# phy_pcs_lane_registers: IP-XACT component
VLNV cadence:cdns_lib:phy_pcs_lane_registers:1685-2009

## Address spaces and blocks
sd3101_t4_registers.sd3101_phy_registers: base 0x34000, range 0x3ff, width 32

## Registers
Registers are 32-bit, read-write, reset 0x0 unless marked. A register's access mark holds for its fields unless they carry their own. Offsets are from the block's base; lines under a group give offsets from that group; [hi:lo] are bit positions; {n}, {i} and the like mark numbered series; 'fields as' and 'values as' point back to an identical list; <NAME> marks a mode.

## sd3101_t4_registers.sd3101_phy_registers
Base 0x00034000
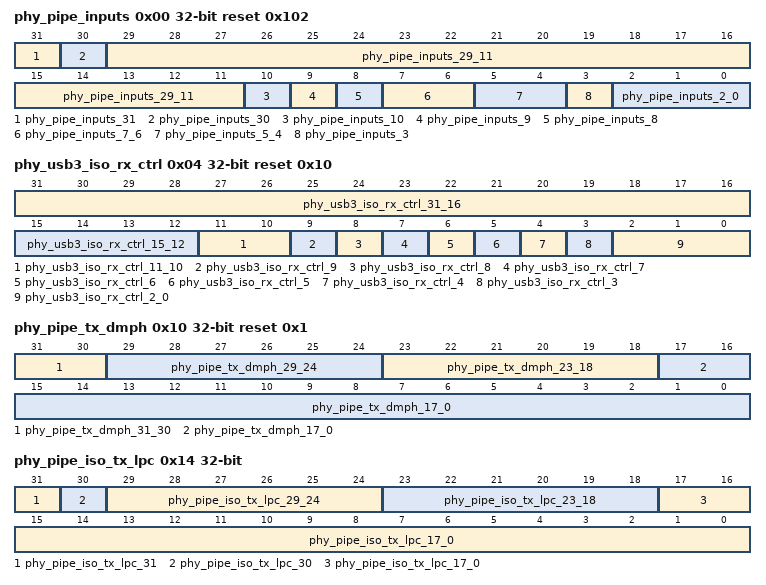
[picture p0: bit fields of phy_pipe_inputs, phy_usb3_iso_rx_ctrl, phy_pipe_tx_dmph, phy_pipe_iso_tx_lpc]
0x00 phy_pipe_inputs reset 0x102 — PIPE7 inputs register
  [31] phy_pipe_inputs_31 ro — RSVD2
  [30] phy_pipe_inputs_30 ro — CTLR_INT
  [29:11] phy_pipe_inputs_29_11 ro — RSVD
  [10] phy_pipe_inputs_10 ro — RX_TERM
  [9] phy_pipe_inputs_9 ro — TX_DET_RX
  [8] phy_pipe_inputs_8 ro — TX_ELEC_IDL
  [7:6] phy_pipe_inputs_7_6 ro — RSVD
  [5:4] phy_pipe_inputs_5_4 ro — RATE
  [3] phy_pipe_inputs_3 ro — RSVD
  [2:0] phy_pipe_inputs_2_0 ro — PWRDWN
0x04 phy_usb3_iso_rx_ctrl reset 0x10 — PHY USB3 RX control signal isolation register
  [31:16] phy_usb3_iso_rx_ctrl_31_16 ro — RSVD
  [15:12] phy_usb3_iso_rx_ctrl_15_12 ro — PIPE4_DATA_K
  [11:10] phy_usb3_iso_rx_ctrl_11_10 ro — RSVD
  [9] phy_usb3_iso_rx_ctrl_9 — PIPE4_RX_EQ
  [8] phy_usb3_iso_rx_ctrl_8 — PIPE4_RX_TERMINATION
  [7] phy_usb3_iso_rx_ctrl_7 — PIPE4_RX_POL
  [6] phy_usb3_iso_rx_ctrl_6 ro — RSVD
  [5] phy_usb3_iso_rx_ctrl_5 ro — PIPE4_RX_VALID
  [4] phy_usb3_iso_rx_ctrl_4 ro — PIPE4_RX_ELEC_IDLE
  [3] phy_usb3_iso_rx_ctrl_3 ro — RSVD
  [2:0] phy_usb3_iso_rx_ctrl_2_0 ro — PIPE4_RX_STATUS
0x10 phy_pipe_tx_dmph reset 0x1 — PIPE MB Tx deemphasis register
  [31:30] phy_pipe_tx_dmph_31_30 ro — RSVD
  [29:24] phy_pipe_tx_dmph_29_24 ro — TX_PRE_IDX
  [23:18] phy_pipe_tx_dmph_23_18 ro — RSVD
  [17:0] phy_pipe_tx_dmph_17_0 ro — TX_DEEMPH
0x14 phy_pipe_iso_tx_lpc — PIPE MB TX local preset coefficients isolation register
  [31] phy_pipe_iso_tx_lpc_31 ro — VALID
  [30] phy_pipe_iso_tx_lpc_30 — GET_PRESET
  [29:24] phy_pipe_iso_tx_lpc_29_24 — INDEX
  [23:18] phy_pipe_iso_tx_lpc_23_18 ro — RSVD0
  [17:0] phy_pipe_iso_tx_lpc_17_0 ro — COEFF
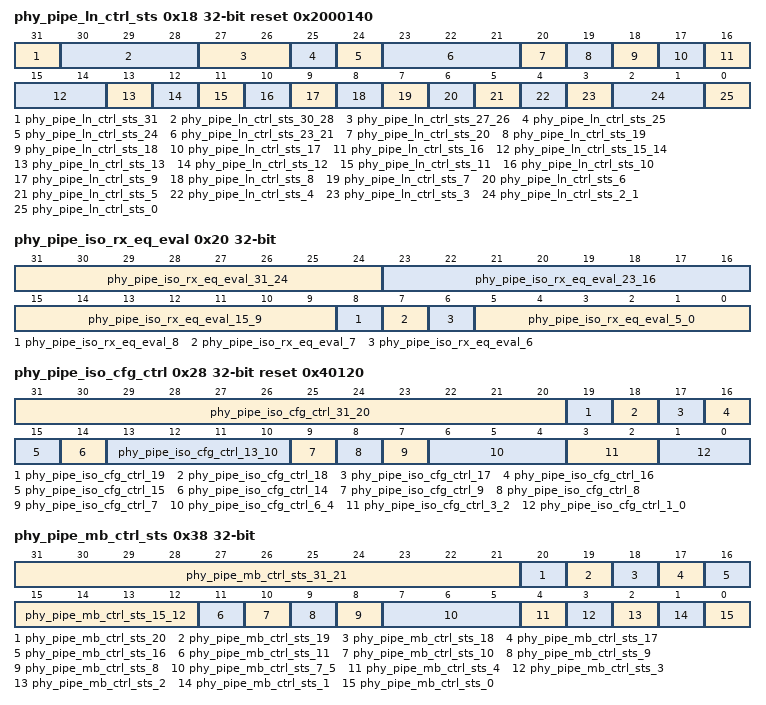
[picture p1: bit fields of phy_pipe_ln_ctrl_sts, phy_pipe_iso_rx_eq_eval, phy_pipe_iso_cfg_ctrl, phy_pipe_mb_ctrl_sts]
0x18 phy_pipe_ln_ctrl_sts reset 0x2000140 — PIPE lane control and status register
  [31] phy_pipe_ln_ctrl_sts_31 ro — TX_SWNG
  [30:28] phy_pipe_ln_ctrl_sts_30_28 ro — TX_MGN
  [27:26] phy_pipe_ln_ctrl_sts_27_26 ro — RSVD2
  [25] phy_pipe_ln_ctrl_sts_25 write-1-sets — SUSPEND_ACK
  [24] phy_pipe_ln_ctrl_sts_24 write-1-sets — DATA_PATH_OVD
  [23:21] phy_pipe_ln_ctrl_sts_23_21 ro — NELD_POS
  [20] phy_pipe_ln_ctrl_sts_20 ro — INVALID
  [19] phy_pipe_ln_ctrl_sts_19 write-1-sets — RX_IDL_OVD
  [18] phy_pipe_ln_ctrl_sts_18 write-1-sets — RX_IDL_VAL
  [17] phy_pipe_ln_ctrl_sts_17 write-1-sets — RX_VLD_OVD
  [16] phy_pipe_ln_ctrl_sts_16 write-1-sets — RX_VLD_VAL
  [15:14] phy_pipe_ln_ctrl_sts_15_14 ro — RSVD0
  [13] phy_pipe_ln_ctrl_sts_13 write-1-sets — LN_MGN_SEL
  [12] phy_pipe_ln_ctrl_sts_12 ro — NELD_ENABLE
  [11] phy_pipe_ln_ctrl_sts_11 ro — GET_TX_COEFF
  [10] phy_pipe_ln_ctrl_sts_10 ro — RXEQ_TRN
  [9] phy_pipe_ln_ctrl_sts_9 ro — IORECAL
  [8] phy_pipe_ln_ctrl_sts_8 ro — PHY_STATUS
  [7] phy_pipe_ln_ctrl_sts_7 ro — RSVD
  [6] phy_pipe_ln_ctrl_sts_6 write-1-sets — FS_LF_VLD
  [5] phy_pipe_ln_ctrl_sts_5 ro — TX_COEFF_VLD
  [4] phy_pipe_ln_ctrl_sts_4 ro — RSVD
  [3] phy_pipe_ln_ctrl_sts_3 write-1-sets — RXEQEVAL_SEL
  [2:1] phy_pipe_ln_ctrl_sts_2_1 ro — RSVD
  [0] phy_pipe_ln_ctrl_sts_0 ro — RXEQEVAL_CMP
0x1C phy_pipe_ln_ctrl_sts_clr reset 0x8C — PIPE lane control and status clear register
  [31:0] phy_pipe_ln_ctrl_sts_clr_31_0 write-1-clears — CLR
0x20 phy_pipe_iso_rx_eq_eval — PIPE RX equalization evaluation isolation register
  [31:24] phy_pipe_iso_rx_eq_eval_31_24 ro — RSVD2
  [23:16] phy_pipe_iso_rx_eq_eval_23_16 ro — FOM
  [15:9] phy_pipe_iso_rx_eq_eval_15_9 ro — RSVD1
  [8] phy_pipe_iso_rx_eq_eval_8 — RXEQEVAL
  [7] phy_pipe_iso_rx_eq_eval_7 ro — RSVD0
  [6] phy_pipe_iso_rx_eq_eval_6 ro — RXEQEVAL_CMP
  [5:0] phy_pipe_iso_rx_eq_eval_5_0 ro — DIR_CHG
0x24 phy_usb3_iso_tx_data — PHY USB3 TX Data isolation register
  [31:0] phy_usb3_iso_tx_data_31_0 — TX_DATA
0x28 phy_pipe_iso_cfg_ctrl reset 0x40120 — PIPE7 configuration and control signal isolation register
  [31:20] phy_pipe_iso_cfg_ctrl_31_20 ro — RSVD
  [19] phy_pipe_iso_cfg_ctrl_19 — STAND_BY
  [18] phy_pipe_iso_cfg_ctrl_18 ro — RX_ELEC_IDL
  [17] phy_pipe_iso_cfg_ctrl_17 ro — RX_VALID
  [16] phy_pipe_iso_cfg_ctrl_16 — RX_TERM
  [15] phy_pipe_iso_cfg_ctrl_15 — TX_CMN_MD_DIS
  [14] phy_pipe_iso_cfg_ctrl_14 — RX_IDL_DET_DIS
  [13:10] phy_pipe_iso_cfg_ctrl_13_10 ro — RSVD2
  [9] phy_pipe_iso_cfg_ctrl_9 — TX_DET_RX
  [8] phy_pipe_iso_cfg_ctrl_8 — TX_ELEC_IDLE
  [7] phy_pipe_iso_cfg_ctrl_7 ro — RSVD1
  [6:4] phy_pipe_iso_cfg_ctrl_6_4 — PWRDN
  [3:2] phy_pipe_iso_cfg_ctrl_3_2 ro — RSVD0
  [1:0] phy_pipe_iso_cfg_ctrl_1_0 — RATE
0x38 phy_pipe_mb_ctrl_sts — PHY PIPE messagebus control and status register
  [31:21] phy_pipe_mb_ctrl_sts_31_21 ro — RSVD
  [20] phy_pipe_mb_ctrl_sts_20 ro — WR_ACK_RCVD
  [19] phy_pipe_mb_ctrl_sts_19 ro — COM_WR_RCVD
  [18] phy_pipe_mb_ctrl_sts_18 ro — MSD2_VLD
  [17] phy_pipe_mb_ctrl_sts_17 ro — MSD1_VLD
  [16] phy_pipe_mb_ctrl_sts_16 ro — MSG0_VLD
  [15:12] phy_pipe_mb_ctrl_sts_15_12 ro — RSVD1
  [11] phy_pipe_mb_ctrl_sts_11 ro — ERR_CNT_FLAG
  [10] phy_pipe_mb_ctrl_sts_10 ro — SMP_CNT_FLAG
  [9] phy_pipe_mb_ctrl_sts_9 write-1-clears — ADDR_INVLD_COM
  [8] phy_pipe_mb_ctrl_sts_8 write-1-clears — ADDR_INVLD_UNCOM
  [7:5] phy_pipe_mb_ctrl_sts_7_5 ro — RSVD0
  [4] phy_pipe_mb_ctrl_sts_4 — CTLR_SOFT_RST
  [3] phy_pipe_mb_ctrl_sts_3 — PMA_SOFT_RST
  [2] phy_pipe_mb_ctrl_sts_2 — TX_SOFT_RST
  [1] phy_pipe_mb_ctrl_sts_1 — RX_SOFT_RST
  [0] phy_pipe_mb_ctrl_sts_0 — SOFT_RST
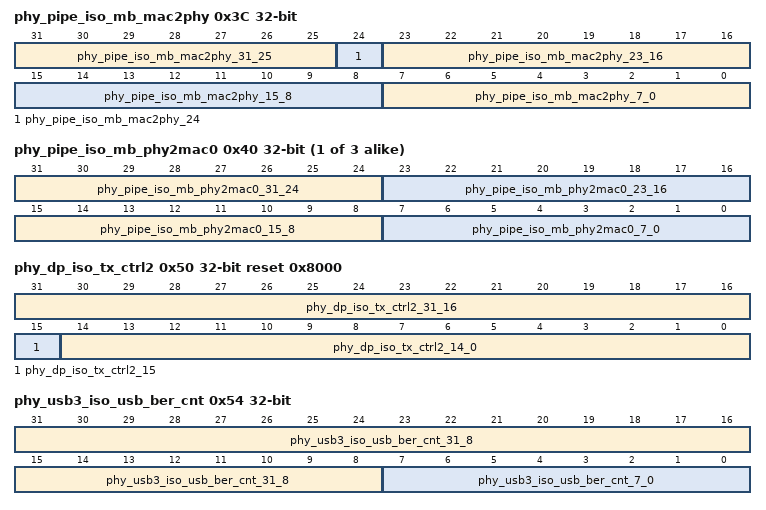
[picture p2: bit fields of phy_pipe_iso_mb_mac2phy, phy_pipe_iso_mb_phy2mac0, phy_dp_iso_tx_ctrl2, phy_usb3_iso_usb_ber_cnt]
0x3C phy_pipe_iso_mb_mac2phy — PHY PIPE MesssageBus MAC-to-PHY isolation register
  [31:25] phy_pipe_iso_mb_mac2phy_31_25 ro — RSVD
  [24] phy_pipe_iso_mb_mac2phy_24 wo — M2P_START
  [23:16] phy_pipe_iso_mb_mac2phy_23_16 — M2P_DATA2
  [15:8] phy_pipe_iso_mb_mac2phy_15_8 — M2P_DATA1
  [7:0] phy_pipe_iso_mb_mac2phy_7_0 — M2P_DATA0
{0x40+4i} phy_pipe_iso_mb_phy2mac{i} (i=0..2) — PHY PIPE MesssageBus PHY-to-MAC isolation register {i}
  [31:24] phy_pipe_iso_mb_phy2mac{i}_31_24 ro — RSVD
  [23:16] phy_pipe_iso_mb_phy2mac{i}_23_16 ro — P2M_DATA2
  [15:8] phy_pipe_iso_mb_phy2mac{i}_15_8 ro — P2M_DATA1
  [7:0] phy_pipe_iso_mb_phy2mac{i}_7_0 ro — P2M_DATA0
0x4C phy_dp_iso_tx_ctrl1 — DP TX control1 signal isolation register
  [31:0] phy_dp_iso_tx_ctrl1_31_0 — TX_TD
0x50 phy_dp_iso_tx_ctrl2 reset 0x8000 — DP TX control2 signal isolation register
  [31:16] phy_dp_iso_tx_ctrl2_31_16 ro — RSVD
  [15] phy_dp_iso_tx_ctrl2_15 — TX_ELEC_IDLE
  [14:0] phy_dp_iso_tx_ctrl2_14_0 ro — RSVD
0x54 phy_usb3_iso_usb_ber_cnt — PHY USB3 USB Gen 1 loopback slave BER count register
  [31:8] phy_usb3_iso_usb_ber_cnt_31_8 ro — RSVD
  [7:0] phy_usb3_iso_usb_ber_cnt_7_0 ro — LPBK_ERR_CNT
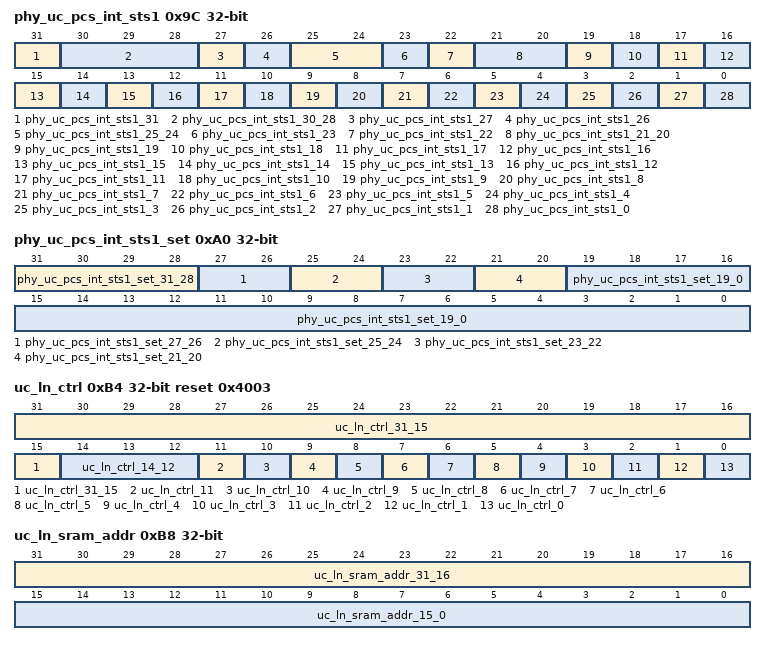
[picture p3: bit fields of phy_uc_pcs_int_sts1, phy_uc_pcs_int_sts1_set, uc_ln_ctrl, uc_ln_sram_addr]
0x9C phy_uc_pcs_int_sts1 — PHY uController PCS interrupt status 1 register
  [31] phy_uc_pcs_int_sts1_31 ro — CTLR_INT
  [30:28] phy_uc_pcs_int_sts1_30_28 ro — RSVD
  [27] phy_uc_pcs_int_sts1_27 write-1-clears — UNCORR_ERR
  [26] phy_uc_pcs_int_sts1_26 write-1-clears — CORR_ERR
  [25:24] phy_uc_pcs_int_sts1_25_24 ro — RSVD
  [23] phy_uc_pcs_int_sts1_23 write-1-clears — RX_INVLD
  [22] phy_uc_pcs_int_sts1_22 write-1-clears — IORECAL
  [21:20] phy_uc_pcs_int_sts1_21_20 ro — RSVD
  [19] phy_uc_pcs_int_sts1_19 write-1-clears — RXEQ_IN_PROG
  [18] phy_uc_pcs_int_sts1_18 write-1-clears — RXEQ_TRN
  [17] phy_uc_pcs_int_sts1_17 write-1-clears — RXEQEVAL_FALL
  [16] phy_uc_pcs_int_sts1_16 write-1-clears — RXEQEVAL_RISE
  [15] phy_uc_pcs_int_sts1_15 write-1-clears — RXELECIDL_FALL
  [14] phy_uc_pcs_int_sts1_14 write-1-clears — RXELECIDL_RISE
  [13] phy_uc_pcs_int_sts1_13 write-1-clears — RX_VLD_RISE
  [12] phy_uc_pcs_int_sts1_12 write-1-clears — RX_VLD_RISE
  [11] phy_uc_pcs_int_sts1_11 write-1-clears — TX_DEEMPH
  [10] phy_uc_pcs_int_sts1_10 write-1-clears — PHYSTS_FALL
  [9] phy_uc_pcs_int_sts1_9 write-1-clears — PHYSTS_RISE
  [8] phy_uc_pcs_int_sts1_8 write-1-clears — PHYSTS_STRB
  [7] phy_uc_pcs_int_sts1_7 write-1-clears — TX_MGN_SWNG
  [6] phy_uc_pcs_int_sts1_6 write-1-clears — GET_COEFF
  [5] phy_uc_pcs_int_sts1_5 write-1-clears — TXELECIDL_FALL
  [4] phy_uc_pcs_int_sts1_4 write-1-clears — TXELECIDL_RISE
  [3] phy_uc_pcs_int_sts1_3 write-1-clears — TXDETRX_FALL
  [2] phy_uc_pcs_int_sts1_2 write-1-clears — TXDETRX_RISE
  [1] phy_uc_pcs_int_sts1_1 write-1-clears — RATE
  [0] phy_uc_pcs_int_sts1_0 write-1-clears — PWRDN
0xA0 phy_uc_pcs_int_sts1_set — PHY uController PCS interrupt status 1 set register
  [31:28] phy_uc_pcs_int_sts1_set_31_28 ro — RSVD
  [27:26] phy_uc_pcs_int_sts1_set_27_26 write-1-sets — SET
  [25:24] phy_uc_pcs_int_sts1_set_25_24 ro — RSVD
  [23:22] phy_uc_pcs_int_sts1_set_23_22 write-1-sets — SET
  [21:20] phy_uc_pcs_int_sts1_set_21_20 ro — RSVD
  [19:0] phy_uc_pcs_int_sts1_set_19_0 write-1-sets — SET
0xA4 phy_ln_uc_pcs_int_sts1_en — PHY lane-level uController PCS interrupt status 1 enable register
  [31:0] phy_ln_uc_pcs_int_sts1_en_31_0 — LN_ENABLE
0xA8 phy_top_uc_pcs_int_sts1_en — PHY top-level uController PCS interrupt status 1 enable register
  [31:0] phy_top_uc_pcs_int_sts1_en_31_0 — TOP_ENABLE
0xAC phy_ln_uc_pcs_en_int_sts1 — PHY lane uController enabled PCS interrupt status 1 register
  [31:0] phy_ln_uc_pcs_en_int_sts1_31_0 ro — ENBLD_INT_LN
0xB0 phy_top_uc_ln_en_int_sts1 — PHY top uController PCS enabled interrupt status 1 register
  [31:0] phy_top_uc_ln_en_int_sts1_31_0 ro — ENBLD_INT_TOP
0xB4 uc_ln_ctrl reset 0x4003 — PHY lane uController control register
  [31:15] uc_ln_ctrl_31_15 ro — RSVD2
  [14:12] uc_ln_ctrl_14_12 — IRAM_BASE
  [11] uc_ln_ctrl_11 — AUTO_INC_DIS
  [10] uc_ln_ctrl_10 ro — RSVD1
  [9] uc_ln_ctrl_9 ro — SRAM_INIT_DN
  [8] uc_ln_ctrl_8 — SRAM_INIT
  [7] uc_ln_ctrl_7 ro — PWAITMODE
  [6] uc_ln_ctrl_6 — CDB_CLK_GATE
  [5] uc_ln_ctrl_5 — CDB_RESYNC
  [4] uc_ln_ctrl_4 — ECC_EN
  [3] uc_ln_ctrl_3 ro — RSVD0
  [2] uc_ln_ctrl_2 wo — SELF_RST
  [1] uc_ln_ctrl_1 — SOFT_RST
  [0] uc_ln_ctrl_0 — STALL
0xB8 uc_ln_sram_addr — PHY lane uController SRAM address register
  [31:16] uc_ln_sram_addr_31_16 ro — RSVD
  [15:0] uc_ln_sram_addr_15_0 — ADDRESS
{0xBC+4i} uc_ln_scrpad{i} (i=0..7) — PHY lane uController scratchpad/mailbox {i} register
  [31:0] uc_ln_scrpad{i}_31_0 — VALUE
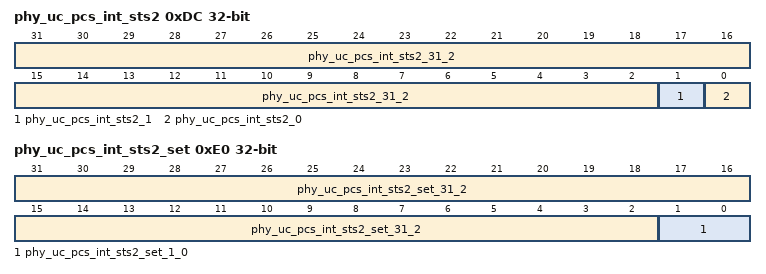
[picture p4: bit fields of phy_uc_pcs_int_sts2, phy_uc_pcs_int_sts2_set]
0xDC phy_uc_pcs_int_sts2 — PHY uController PCS interrupt status 2 register
  [31:2] phy_uc_pcs_int_sts2_31_2 ro — RSVD
  [1] phy_uc_pcs_int_sts2_1 write-1-clears — SUSPEND_FALL
  [0] phy_uc_pcs_int_sts2_0 write-1-clears — SUSPEND_RISE
0xE0 phy_uc_pcs_int_sts2_set — PHY uController PCS interrupt status 2 set register
  [31:2] phy_uc_pcs_int_sts2_set_31_2 ro — RSVD
  [1:0] phy_uc_pcs_int_sts2_set_1_0 write-1-sets — SET
0xE4 phy_ln_uc_pcs_int_sts2_en — PHY lane-level uController PCS interrupt status 2 enable register
  [31:0] phy_ln_uc_pcs_int_sts2_en_31_0 — LN_ENABLE
0xE8 phy_top_uc_pcs_int_sts2_en — PHY top-level uController PCS interrupt status 2 enable register
  [31:0] phy_top_uc_pcs_int_sts2_en_31_0 — TOP_ENABLE
0xEC phy_ln_uc_pcs_en_int_sts2 — PHY lane uController enabled PCS interrupt status 2 register
  [31:0] phy_ln_uc_pcs_en_int_sts2_31_0 ro — ENBLD_INT_LN
0xF0 phy_top_uc_ln_en_int_sts2 — PHY top uController PCS enabled interrupt status 2 register
  [31:0] phy_top_uc_ln_en_int_sts2_31_0 ro — ENBLD_INT_TOP
0x100 uc_ln_sram_access — PHY lane uController SRAM access register
  [31:0] uc_ln_sram_access_31_0 — ACCESS
